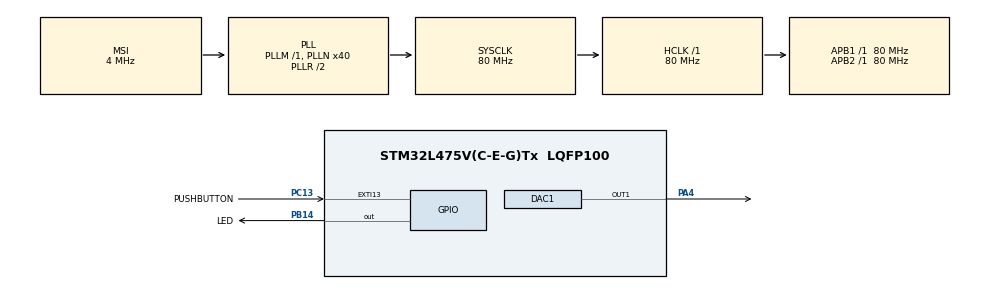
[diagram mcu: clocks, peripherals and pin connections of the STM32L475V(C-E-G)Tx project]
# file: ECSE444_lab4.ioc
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DAC1.DAC_Trigger-DAC_OUT1=DAC_TRIGGER_T2_TRGO
Dma.DAC_CH1.0.Direction=DMA_MEMORY_TO_PERIPH
Dma.DAC_CH1.0.Instance=DMA1_Channel3
Dma.DAC_CH1.0.MemDataAlignment=DMA_MDATAALIGN_WORD
Dma.DAC_CH1.0.MemInc=DMA_MINC_ENABLE
Dma.DAC_CH1.0.Mode=DMA_CIRCULAR
Dma.DAC_CH1.0.PeriphDataAlignment=DMA_PDATAALIGN_WORD
Dma.DAC_CH1.0.PeriphInc=DMA_PINC_DISABLE
Dma.DAC_CH1.0.Priority=DMA_PRIORITY_LOW
Dma.Request0=DAC_CH1
Mcu.Family=STM32L4
Mcu.Name=STM32L475V(C-E-G)Tx
Mcu.Package=LQFP100
NVIC.DMA1_Channel3_IRQn=true\:0\:0\:false\:false\:true\:false\:true\:true
NVIC.EXTI15_10_IRQn=true\:0\:0\:false\:false\:true\:true\:true\:true
NVIC.PriorityGroup=NVIC_PRIORITYGROUP_4
NVIC.TIM2_IRQn=true\:0\:0\:false\:false\:true\:true\:true\:true
PA13\ (JTMS-SWDIO).Signal=SYS_JTMS-SWDIO
PA4.Signal=COMP_DAC11_group
PB14.GPIO_Label=LED
PB14.Signal=GPIO_Output
PB3\ (JTDO-TRACESWO).Signal=SYS_JTDO-SWO
PC13.GPIO_Label=PUSHBUTTON
PC13.Signal=GPXTI13
ProjectManager.HeapSize=0x200
ProjectManager.StackSize=0x400
ProjectManager.TargetToolchain=STM32CubeIDE
RCC.ADCFreq_Value=48000000
RCC.AHBFreq_Value=80000000
RCC.APB1Freq_Value=80000000
RCC.APB1TimFreq_Value=80000000
RCC.APB2Freq_Value=80000000
RCC.APB2TimFreq_Value=80000000
RCC.CortexFreq_Value=80000000
RCC.HCLKFreq_Value=80000000
RCC.HSE_VALUE=8000000
RCC.HSI_VALUE=16000000
RCC.LSE_VALUE=32768
RCC.MSI_VALUE=4000000
RCC.PLLN=40
RCC.PLLSAI1N=24
RCC.SYSCLKFreq_VALUE=80000000
RCC.SYSCLKSource=RCC_SYSCLKSOURCE_PLLCLK
RCC.USBFreq_Value=48000000
RCC.VCOOutputFreq_Value=160000000
SH.COMP_DAC11_group.0=DAC1_OUT1,DAC_OUT1
TIM2.Period=1995
TIM2.TIM_MasterOutputTrigger=TIM_TRGO_UPDATE
VP_TIM2_VS_ClockSourceINT.Mode=Internal
board=B-L475E-IOT01A1

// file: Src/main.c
/* USER CODE BEGIN Header */
/**
  ******************************************************************************
  * @file           : main.c
  * @brief          : Main program body
  ******************************************************************************
  * @attention
  *
  * Copyright (c) 2022 STMicroelectronics.
  * All rights reserved.
  *
  * This software is licensed under terms that can be found in the LICENSE file
  * in the root directory of this software component.
  * If no LICENSE file comes with this software, it is provided AS-IS.
  *
  ******************************************************************************
  */
/* USER CODE END Header */
#include "main.h"

/* USER CODE BEGIN Includes */
#define ARM_MATH_CM4
#include "arm_math.h"
/* USER CODE END Includes */

DAC_HandleTypeDef hdac1;
DMA_HandleTypeDef hdma_dac_ch1;

TIM_HandleTypeDef htim2;

/* USER CODE BEGIN PV */
uint32_t sine4[20]; // 4KHz
uint32_t sine2[40]; // 2KHz
uint32_t sine3[60]; // 1.5KHz
uint32_t sine1[80]; // 1KHz
uint32_t signalno = 0;
uint32_t *signals[4]; // pointer to 3 sine waves
uint32_t signalsizes[4] = {80, 40, 20, 60}; // array sizes for each signal to be used in DMA
uint32_t signalIndex = 0;

// for debugging using SWV
uint32_t wave;
/* USER CODE END PV */

void SystemClock_Config(void);
static void MX_GPIO_Init(void);
static void MX_DMA_Init(void);
static void MX_DAC1_Init(void);
static void MX_TIM2_Init(void);

/* USER CODE BEGIN 0 */
void HAL_GPIO_EXTI_Callback(uint16_t GPIO_Pin) {
	// no need to verify the pin since there are no external interrupts

	// change audio signal on pushbutton press
	HAL_DAC_Stop_DMA(&hdac1, DAC_CHANNEL_1);
	HAL_DAC_Start_DMA(&hdac1, DAC_CHANNEL_1, signals[signalIndex], signalsizes[signalIndex], DAC_ALIGN_12B_R);
	signalIndex = (signalIndex + 1) % 4; // update next signal index

	// toggle LED on PUSHBUTTON push
	HAL_GPIO_TogglePin(LED_GPIO_Port, LED_Pin);
}

// called by TIM interrupt handler
//void HAL_TIM_PeriodElapsedCallback(TIM_HandleTypeDef *htim) {
//    // we should probably check the timer causing the interrupt but YOLO...
////	HAL_DAC_SetValue(&hdac1, DAC_CHANNEL_1, DAC_ALIGN_12B_R, sine2[signalIndex]);
////	signalIndex = (signalIndex + 1) % 40;
//
//	HAL_DAC_SetValue(&hdac1, DAC_CHANNEL_1, DAC_ALIGN_12B_R, sine1[signalIndex]);
//	wave = sine1[signalIndex];
//	signalIndex = (signalIndex + 1) % 80;
////
////	HAL_DAC_SetValue(&hdac1, DAC_CHANNEL_1, DAC_ALIGN_12B_R, sine4[signalIndex]);
////	signalIndex = (signalIndex + 1) % 20;
//}

void initSignals() {
	// 2047 * 2/3 = 1364.66 ~ 1365
	// we scale DAC values to vary over 2/3 of possible dynamic range
	  for (uint32_t i = 0; i < 20; i++) {
		  float r = 3.14 * i / 10.0;
		  sine4[i] = (uint32_t) roundf(1365.0 * (1.0 + arm_sin_f32(r)));

	  }

	  for (uint32_t i = 0; i < 40; i++) {
		  float r = 3.14 * i / 20.0;
		  sine2[i] = (uint32_t) roundf(1365.0 * (1.0 + arm_sin_f32(r)));
	  }

	  for (uint32_t i = 0; i < 80; i++) {
		  float r = 3.14 * i / 40.0;
		  sine1[i] = (uint32_t) roundf(1365.0 * (1.0 + arm_sin_f32(r)));
	  }

	  for (uint32_t i = 0; i < 60; i++) {
	  	  float r = 3.14 * i / 30.0;
	  	  sine3[i] = (uint32_t) roundf(1365.0 * (1.0 + arm_sin_f32(r)));
	  }
	  signals[0] = sine1;
	  signals[1] = sine2;
	  signals[2] = sine4;
	  signals[3] = sine3;

}

/* USER CODE END 0 */

int main(void)
{

  /* MCU Configuration--------------------------------------------------------*/

  /* Reset of all peripherals, Initializes the Flash interface and the Systick. */
  HAL_Init();

  /* Configure the system clock */
  SystemClock_Config();

  /* Initialize all configured peripherals */
  MX_GPIO_Init();
  MX_DMA_Init();
  MX_DAC1_Init();
  MX_TIM2_Init();
  /* USER CODE BEGIN 2 */

  HAL_TIM_Base_Start_IT(&htim2); // start timer in interrupt mode
  HAL_DAC_Start(&hdac1, DAC_CHANNEL_1); // start DAC
  HAL_DAC_Start_DMA(&hdac1, DAC_CHANNEL_1, sine2, 40, DAC_ALIGN_12B_R);

  initSignals();
  /* USER CODE END 2 */

  /* Infinite loop */
  while (1)
  {

  }
}

void SystemClock_Config(void)
{
  RCC_OscInitTypeDef RCC_OscInitStruct = {0};
  RCC_ClkInitTypeDef RCC_ClkInitStruct = {0};

  /** Configure the main internal regulator output voltage
  */
  if (HAL_PWREx_ControlVoltageScaling(PWR_REGULATOR_VOLTAGE_SCALE1) != HAL_OK)
  {
    Error_Handler();
  }

  /** Initializes the RCC Oscillators according to the specified parameters
  * in the RCC_OscInitTypeDef structure.
  */
  RCC_OscInitStruct.OscillatorType = RCC_OSCILLATORTYPE_MSI;
  RCC_OscInitStruct.MSIState = RCC_MSI_ON;
  RCC_OscInitStruct.MSICalibrationValue = 0;
  RCC_OscInitStruct.MSIClockRange = RCC_MSIRANGE_6;
  RCC_OscInitStruct.PLL.PLLState = RCC_PLL_ON;
  RCC_OscInitStruct.PLL.PLLSource = RCC_PLLSOURCE_MSI;
  RCC_OscInitStruct.PLL.PLLM = 1;
  RCC_OscInitStruct.PLL.PLLN = 40;
  RCC_OscInitStruct.PLL.PLLP = RCC_PLLP_DIV7;
  RCC_OscInitStruct.PLL.PLLQ = RCC_PLLQ_DIV2;
  RCC_OscInitStruct.PLL.PLLR = RCC_PLLR_DIV2;
  if (HAL_RCC_OscConfig(&RCC_OscInitStruct) != HAL_OK)
  {
    Error_Handler();
  }

  /** Initializes the CPU, AHB and APB buses clocks
  */
  RCC_ClkInitStruct.ClockType = RCC_CLOCKTYPE_HCLK|RCC_CLOCKTYPE_SYSCLK
                              |RCC_CLOCKTYPE_PCLK1|RCC_CLOCKTYPE_PCLK2;
  RCC_ClkInitStruct.SYSCLKSource = RCC_SYSCLKSOURCE_PLLCLK;
  RCC_ClkInitStruct.AHBCLKDivider = RCC_SYSCLK_DIV1;
  RCC_ClkInitStruct.APB1CLKDivider = RCC_HCLK_DIV1;
  RCC_ClkInitStruct.APB2CLKDivider = RCC_HCLK_DIV1;

  if (HAL_RCC_ClockConfig(&RCC_ClkInitStruct, FLASH_LATENCY_4) != HAL_OK)
  {
    Error_Handler();
  }
}

static void MX_DAC1_Init(void)
{

  DAC_ChannelConfTypeDef sConfig = {0};

  /** DAC Initialization
  */
  hdac1.Instance = DAC1;
  if (HAL_DAC_Init(&hdac1) != HAL_OK)
  {
    Error_Handler();
  }

  /** DAC channel OUT1 config
  */
  sConfig.DAC_SampleAndHold = DAC_SAMPLEANDHOLD_DISABLE;
  sConfig.DAC_Trigger = DAC_TRIGGER_T2_TRGO;
  sConfig.DAC_OutputBuffer = DAC_OUTPUTBUFFER_ENABLE;
  sConfig.DAC_ConnectOnChipPeripheral = DAC_CHIPCONNECT_DISABLE;
  sConfig.DAC_UserTrimming = DAC_TRIMMING_FACTORY;
  if (HAL_DAC_ConfigChannel(&hdac1, &sConfig, DAC_CHANNEL_1) != HAL_OK)
  {
    Error_Handler();
  }

}

static void MX_TIM2_Init(void)
{

  TIM_ClockConfigTypeDef sClockSourceConfig = {0};
  TIM_MasterConfigTypeDef sMasterConfig = {0};

  htim2.Instance = TIM2;
  htim2.Init.Prescaler = 0;
  htim2.Init.CounterMode = TIM_COUNTERMODE_UP;
  htim2.Init.Period = 1995;
  htim2.Init.ClockDivision = TIM_CLOCKDIVISION_DIV1;
  htim2.Init.AutoReloadPreload = TIM_AUTORELOAD_PRELOAD_DISABLE;
  if (HAL_TIM_Base_Init(&htim2) != HAL_OK)
  {
    Error_Handler();
  }
  sClockSourceConfig.ClockSource = TIM_CLOCKSOURCE_INTERNAL;
  if (HAL_TIM_ConfigClockSource(&htim2, &sClockSourceConfig) != HAL_OK)
  {
    Error_Handler();
  }
  sMasterConfig.MasterOutputTrigger = TIM_TRGO_UPDATE;
  sMasterConfig.MasterSlaveMode = TIM_MASTERSLAVEMODE_DISABLE;
  if (HAL_TIMEx_MasterConfigSynchronization(&htim2, &sMasterConfig) != HAL_OK)
  {
    Error_Handler();
  }

}

static void MX_DMA_Init(void)
{

  /* DMA controller clock enable */
  __HAL_RCC_DMA1_CLK_ENABLE();

  /* DMA interrupt init */
  /* DMA1_Channel3_IRQn interrupt configuration */
  HAL_NVIC_SetPriority(DMA1_Channel3_IRQn, 0, 0);
  HAL_NVIC_EnableIRQ(DMA1_Channel3_IRQn);

}

static void MX_GPIO_Init(void)
{
  GPIO_InitTypeDef GPIO_InitStruct = {0};

  /* GPIO Ports Clock Enable */
  __HAL_RCC_GPIOC_CLK_ENABLE();
  __HAL_RCC_GPIOA_CLK_ENABLE();
  __HAL_RCC_GPIOB_CLK_ENABLE();

  /*Configure GPIO pin Output Level */
  HAL_GPIO_WritePin(LED_GPIO_Port, LED_Pin, GPIO_PIN_RESET);

  /*Configure GPIO pin : PUSHBUTTON_Pin */
  GPIO_InitStruct.Pin = PUSHBUTTON_Pin;
  GPIO_InitStruct.Mode = GPIO_MODE_IT_RISING;
  GPIO_InitStruct.Pull = GPIO_NOPULL;
  HAL_GPIO_Init(PUSHBUTTON_GPIO_Port, &GPIO_InitStruct);

  /*Configure GPIO pin : LED_Pin */
  GPIO_InitStruct.Pin = LED_Pin;
  GPIO_InitStruct.Mode = GPIO_MODE_OUTPUT_PP;
  GPIO_InitStruct.Pull = GPIO_NOPULL;
  GPIO_InitStruct.Speed = GPIO_SPEED_FREQ_LOW;
  HAL_GPIO_Init(LED_GPIO_Port, &GPIO_InitStruct);

  /* EXTI interrupt init*/
  HAL_NVIC_SetPriority(EXTI15_10_IRQn, 0, 0);
  HAL_NVIC_EnableIRQ(EXTI15_10_IRQn);

}

void Error_Handler(void)
{
  __disable_irq();
  while (1)
  {
  }
}
